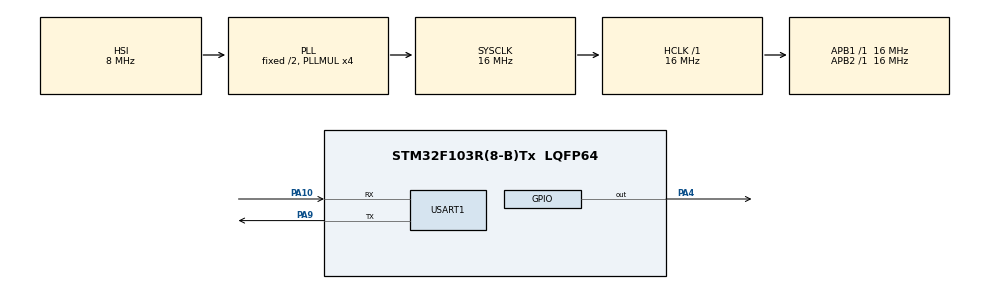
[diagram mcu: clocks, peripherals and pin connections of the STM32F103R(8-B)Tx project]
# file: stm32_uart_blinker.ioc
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Mcu.Family=STM32F1
Mcu.Name=STM32F103R(8-B)Tx
Mcu.Package=LQFP64
NVIC.PriorityGroup=NVIC_PRIORITYGROUP_4
NVIC.USART1_IRQn=true\:0\:0\:false\:false\:true\:true\:true\:true
PA10.Mode=Asynchronous
PA10.Signal=USART1_RX
PA4.Signal=GPIO_Output
PA9.Mode=Asynchronous
PA9.Signal=USART1_TX
ProjectManager.HeapSize=0x200
ProjectManager.StackSize=0x400
ProjectManager.TargetToolchain=STM32CubeIDE
RCC.AHBFreq_Value=16000000
RCC.APB1Freq_Value=16000000
RCC.APB1TimFreq_Value=16000000
RCC.APB2Freq_Value=16000000
RCC.APB2TimFreq_Value=16000000
RCC.HCLKFreq_Value=16000000
RCC.PLLMUL=RCC_PLL_MUL4
RCC.SYSCLKFreq_VALUE=16000000
RCC.SYSCLKSource=RCC_SYSCLKSOURCE_PLLCLK
RCC.USBFreq_Value=16000000
USART1.VirtualMode=VM_ASYNC
VP_SYS_VS_ND.Mode=No_Debug
board=custom

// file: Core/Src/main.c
/* USER CODE BEGIN Header */
/**
  ******************************************************************************
  * @file           : main.c
  * @brief          : Main program body
  ******************************************************************************
  * @attention
  *
  * Copyright (c) 2026 STMicroelectronics.
  * All rights reserved.
  *
  * This software is licensed under terms that can be found in the LICENSE file
  * in the root directory of this software component.
  * If no LICENSE file comes with this software, it is provided AS-IS.
  *
  ******************************************************************************
  */
/* USER CODE END Header */
#include "main.h"

/* USER CODE BEGIN PD */
#define LED_PIN_MASK        (1UL << 4)     /* PA4 */
#define CMD_LED_ON          ((uint8_t)'1')
#define CMD_LED_OFF         ((uint8_t)'0')
/* USER CODE END PD */

UART_HandleTypeDef huart1;

void SystemClock_Config(void);
static void MX_GPIO_Init(void);
static void MX_USART1_UART_Init(void);
/* USER CODE BEGIN PFP */
static void LED_Init(void);
static uint8_t UART1_ReadByte(void);
/* USER CODE END PFP */

/* USER CODE BEGIN 0 */

/**
  * @brief  Configures PA4 as a push-pull output at register level and
  *         drives it low (LED off). Independent of HAL_GPIO_Init.
  * @retval None
  */
static void LED_Init(void)
{
  RCC->APB2ENR |= RCC_APB2ENR_IOPAEN;

  GPIOA->CRL &= ~(GPIO_CRL_MODE4 | GPIO_CRL_CNF4);
  GPIOA->CRL |= (0x2UL << GPIO_CRL_MODE4_Pos); /* MODE4 = 10: output, max 2 MHz, CNF4 = 00: push-pull */

  GPIOA->BSRR = (uint32_t)(LED_PIN_MASK << 16U); /* BR4: force PA4 low */
}

/**
  * @brief  Blocks until USART1 receives a byte and returns it, using
  *         register-level polling of the RXNE flag (no HAL_UART_Receive).
  * @retval Received byte
  */
static uint8_t UART1_ReadByte(void)
{
  while ((USART1->SR & USART_SR_RXNE) == 0U)
  {
    /* wait for a byte from the ESP8266 */
  }

  return (uint8_t)(USART1->DR & 0xFFU);
}

/* USER CODE END 0 */

int main(void)
{

  /* MCU Configuration--------------------------------------------------------*/

  /* Reset of all peripherals, Initializes the Flash interface and the Systick. */
  HAL_Init();

  /* Configure the system clock */
  SystemClock_Config();

  /* Initialize all configured peripherals */
  MX_GPIO_Init();
  MX_USART1_UART_Init();
  /* USER CODE BEGIN 2 */
  LED_Init();
  /* USER CODE END 2 */

  /* Infinite loop */
  /* USER CODE BEGIN WHILE */
  while (1)
  {
    uint8_t cmd = UART1_ReadByte();

    if (cmd == CMD_LED_ON)
    {
      GPIOA->BSRR = LED_PIN_MASK;                   /* BS4: PA4 high -> LED on */
    }
    else if (cmd == CMD_LED_OFF)
    {
      GPIOA->BSRR = (uint32_t)(LED_PIN_MASK << 16U); /* BR4: PA4 low -> LED off */
    }
    else
    {
      /* unrecognized byte: ignore */
    }
    /* USER CODE END WHILE */

  }
}

void SystemClock_Config(void)
{
  RCC_OscInitTypeDef RCC_OscInitStruct = {0};
  RCC_ClkInitTypeDef RCC_ClkInitStruct = {0};

  /** Initializes the RCC Oscillators according to the specified parameters
  * in the RCC_OscInitTypeDef structure.
  */
  RCC_OscInitStruct.OscillatorType = RCC_OSCILLATORTYPE_HSI;
  RCC_OscInitStruct.HSIState = RCC_HSI_ON;
  RCC_OscInitStruct.HSICalibrationValue = RCC_HSICALIBRATION_DEFAULT;
  RCC_OscInitStruct.PLL.PLLState = RCC_PLL_ON;
  RCC_OscInitStruct.PLL.PLLSource = RCC_PLLSOURCE_HSI_DIV2;
  RCC_OscInitStruct.PLL.PLLMUL = RCC_PLL_MUL4;
  if (HAL_RCC_OscConfig(&RCC_OscInitStruct) != HAL_OK)
  {
    Error_Handler();
  }

  /** Initializes the CPU, AHB and APB buses clocks
  */
  RCC_ClkInitStruct.ClockType = RCC_CLOCKTYPE_HCLK|RCC_CLOCKTYPE_SYSCLK
                              |RCC_CLOCKTYPE_PCLK1|RCC_CLOCKTYPE_PCLK2;
  RCC_ClkInitStruct.SYSCLKSource = RCC_SYSCLKSOURCE_PLLCLK;
  RCC_ClkInitStruct.AHBCLKDivider = RCC_SYSCLK_DIV1;
  RCC_ClkInitStruct.APB1CLKDivider = RCC_HCLK_DIV1;
  RCC_ClkInitStruct.APB2CLKDivider = RCC_HCLK_DIV1;

  if (HAL_RCC_ClockConfig(&RCC_ClkInitStruct, FLASH_LATENCY_0) != HAL_OK)
  {
    Error_Handler();
  }
}

static void MX_USART1_UART_Init(void)
{

  huart1.Instance = USART1;
  huart1.Init.BaudRate = 115200;
  huart1.Init.WordLength = UART_WORDLENGTH_8B;
  huart1.Init.StopBits = UART_STOPBITS_1;
  huart1.Init.Parity = UART_PARITY_NONE;
  huart1.Init.Mode = UART_MODE_TX_RX;
  huart1.Init.HwFlowCtl = UART_HWCONTROL_NONE;
  huart1.Init.OverSampling = UART_OVERSAMPLING_16;
  if (HAL_UART_Init(&huart1) != HAL_OK)
  {
    Error_Handler();
  }

}

static void MX_GPIO_Init(void)
{
  GPIO_InitTypeDef GPIO_InitStruct = {0};

  /* GPIO Ports Clock Enable */
  __HAL_RCC_GPIOA_CLK_ENABLE();

  /*Configure GPIO pin Output Level */
  HAL_GPIO_WritePin(GPIOA, GPIO_PIN_4, GPIO_PIN_RESET);

  /*Configure GPIO pin : PA4 */
  GPIO_InitStruct.Pin = GPIO_PIN_4;
  GPIO_InitStruct.Mode = GPIO_MODE_OUTPUT_PP;
  GPIO_InitStruct.Pull = GPIO_NOPULL;
  GPIO_InitStruct.Speed = GPIO_SPEED_FREQ_LOW;
  HAL_GPIO_Init(GPIOA, &GPIO_InitStruct);

}

void Error_Handler(void)
{
  __disable_irq();
  while (1)
  {
  }
}
